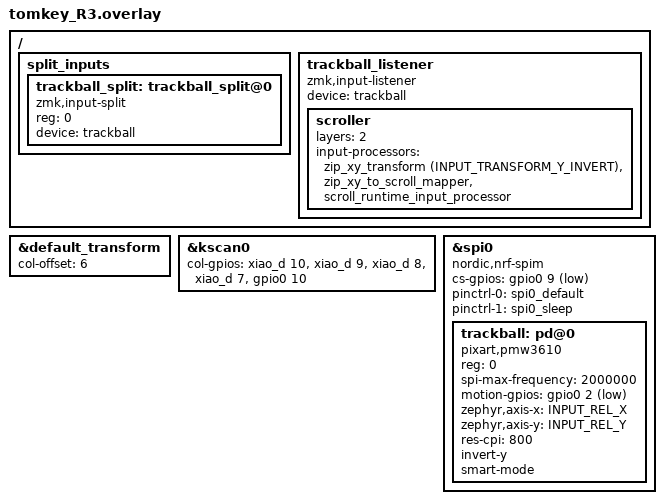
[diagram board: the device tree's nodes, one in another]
#include "../tomkey/tomkey.dtsi"
#include <input/processors.dtsi>
#include <input/processors/runtime-input-processor.dtsi>
#include <dt-bindings/zmk/input_transform.h>
#include <zephyr/dt-bindings/input/input-event-codes.h>

&default_transform {
    col-offset = <6>;
};

&kscan0 {
        col-gpios
            = <&xiao_d 10 GPIO_ACTIVE_HIGH>
            , <&xiao_d 9 GPIO_ACTIVE_HIGH>
            , <&xiao_d 8 GPIO_ACTIVE_HIGH>
            , <&xiao_d 7 GPIO_ACTIVE_HIGH>
            , <&gpio0 10 GPIO_ACTIVE_HIGH>
            ;
};

&spi0 {
    status = "okay";
    cs-gpios =  <&gpio0 9 GPIO_ACTIVE_LOW>;
    pinctrl-0 = <&spi0_default>;
    pinctrl-1 = <&spi0_sleep>;
    pinctrl-names = "default", "sleep";
    compatible = "nordic,nrf-spim";

    trackball: pd@0 {
        status = "disabled";
        compatible = "pixart,pmw3610";
        reg = <0>;
        spi-max-frequency = <2000000>;
        motion-gpios = <&gpio0 2 (GPIO_ACTIVE_LOW | GPIO_PULL_UP)>;
        zephyr,axis-x = <INPUT_REL_X>;
        zephyr,axis-y = <INPUT_REL_Y>;
        res-cpi = <800>;
        invert-y;
        smart-mode;
    };
};

/ {
    split_inputs {
        #address-cells = <1>;
        #size-cells = <0>;

        trackball_split: trackball_split@0 {
            compatible = "zmk,input-split";
            reg = <0>;
        };
    };

    trackball_listener: trackball_listener {
        compatible = "zmk,input-listener";
        status = "disabled";
        device = <&trackball>;
    };
};

&trackball {
    status = "okay";
};

&trackball_listener {
    status = "okay";
    device = <&trackball>;
    /* Peripheral 側では RIP を使用せず、Central 側で一括制御する */


    scroller {
        /* layer 2 (SCROLL): カーソル移動をスクロールに変換 */
        layers = <2>;
        input-processors = <
            &zip_xy_transform (INPUT_TRANSFORM_Y_INVERT)
            &zip_xy_to_scroll_mapper
            &scroll_runtime_input_processor
        >;
    };
};

&trackball_split {
    device = <&trackball>;
};
